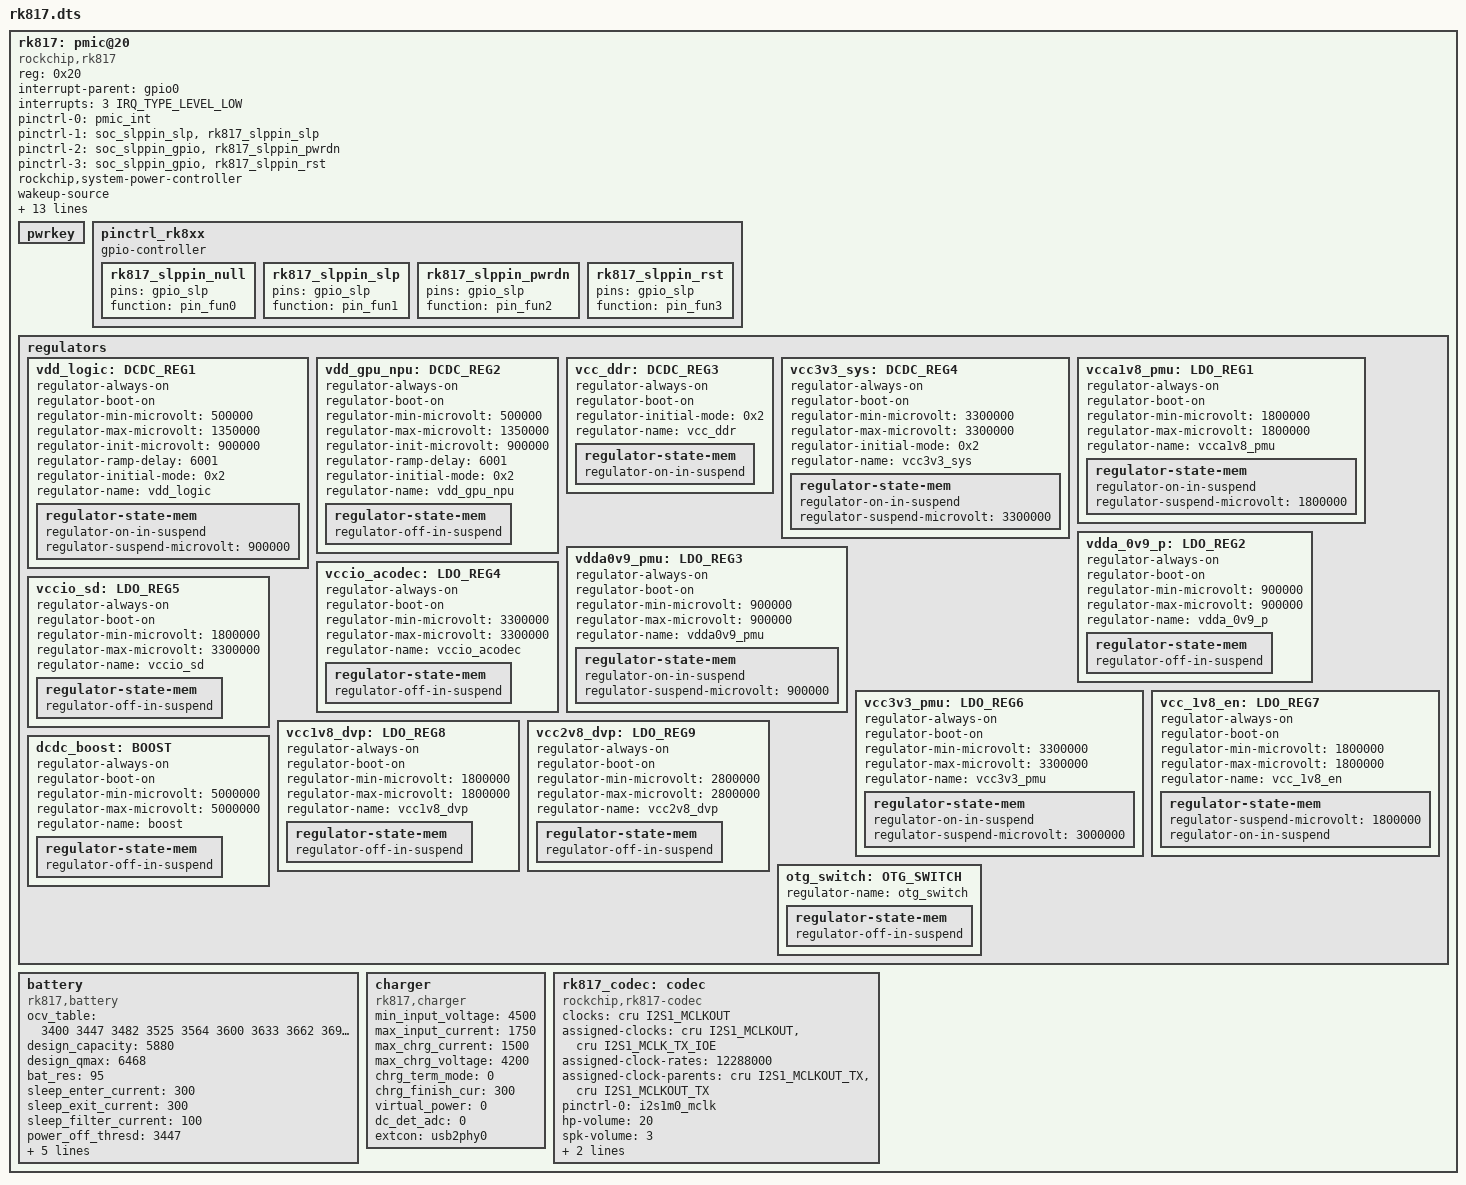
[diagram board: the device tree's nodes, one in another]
	rk817: pmic@20 {
		compatible = "rockchip,rk817";
		reg = <0x20>;
		interrupt-parent = <&gpio0>;
		interrupts = <3 IRQ_TYPE_LEVEL_LOW>;

		pinctrl-names = "default", "pmic-sleep",
				"pmic-power-off", "pmic-reset";
		pinctrl-0 = <&pmic_int>;
		pinctrl-1 = <&soc_slppin_slp>, <&rk817_slppin_slp>;
		pinctrl-2 = <&soc_slppin_gpio>, <&rk817_slppin_pwrdn>;
		pinctrl-3 = <&soc_slppin_gpio>, <&rk817_slppin_rst>;
		rockchip,system-power-controller;
		wakeup-source;
		#clock-cells = <1>;
		clock-output-names = "rk808-clkout1", "rk808-clkout2";
		//fb-inner-reg-idxs = <2>;
		/* 1: rst regs (default in codes), 0: rst the pmic */
		pmic-reset-func = <0>;
		/* not save the PMIC_POWER_EN register in uboot */
		not-save-power-en = <1>;

		vcc1-supply = <&vcc_sys>;
		vcc2-supply = <&vcc_sys>;
		vcc3-supply = <&vcc_sys>;
		vcc4-supply = <&vcc_sys>;
		vcc5-supply = <&vcc_sys>;
		vcc6-supply = <&vcc_sys>;
		vcc7-supply = <&vcc_sys>;
		vcc8-supply = <&vcc_sys>;
		vcc9-supply = <&dcdc_boost>;

		pwrkey {
			status = "okay";
		};

		pinctrl_rk8xx: pinctrl_rk8xx {
			gpio-controller;
			#gpio-cells = <2>;

			rk817_slppin_null: rk817_slppin_null {
				pins = "gpio_slp";
				function = "pin_fun0";
			};

			rk817_slppin_slp: rk817_slppin_slp {
				pins = "gpio_slp";
				function = "pin_fun1";
			};

			rk817_slppin_pwrdn: rk817_slppin_pwrdn {
				pins = "gpio_slp";
				function = "pin_fun2";
			};

			rk817_slppin_rst: rk817_slppin_rst {
				pins = "gpio_slp";
				function = "pin_fun3";
			};
		};

		regulators {
			vdd_logic: DCDC_REG1 {
				regulator-always-on;
				regulator-boot-on;
				regulator-min-microvolt = <500000>;
				regulator-max-microvolt = <1350000>;
				regulator-init-microvolt = <900000>;
				regulator-ramp-delay = <6001>;
				regulator-initial-mode = <0x2>;
				regulator-name = "vdd_logic";
				regulator-state-mem {
					regulator-on-in-suspend;
					regulator-suspend-microvolt = <900000>;
				};
			};

			vdd_gpu_npu: DCDC_REG2 {
				regulator-always-on;
				regulator-boot-on;
				regulator-min-microvolt = <500000>;
				regulator-max-microvolt = <1350000>;
				regulator-init-microvolt = <900000>;
				regulator-ramp-delay = <6001>;
				regulator-initial-mode = <0x2>;
				regulator-name = "vdd_gpu_npu";
				regulator-state-mem {
					regulator-off-in-suspend;
				};
			};

			vcc_ddr: DCDC_REG3 {
				regulator-always-on;
				regulator-boot-on;
				regulator-initial-mode = <0x2>;
				regulator-name = "vcc_ddr";
				regulator-state-mem {
					regulator-on-in-suspend;
				};
			};

			vcc3v3_sys: DCDC_REG4 {
				regulator-always-on;
				regulator-boot-on;
				regulator-min-microvolt = <3300000>;
				regulator-max-microvolt = <3300000>;
				regulator-initial-mode = <0x2>;
				regulator-name = "vcc3v3_sys";
				regulator-state-mem {
					regulator-on-in-suspend;
					regulator-suspend-microvolt = <3300000>;
				};
			};

			vcca1v8_pmu: LDO_REG1 {
				regulator-always-on;
				regulator-boot-on;
				regulator-min-microvolt = <1800000>;
				regulator-max-microvolt = <1800000>;
				regulator-name = "vcca1v8_pmu";
				regulator-state-mem {
					regulator-on-in-suspend;
					regulator-suspend-microvolt = <1800000>;
				};
			};

			vdda_0v9_p: LDO_REG2 {
				regulator-always-on;
				regulator-boot-on;
				regulator-min-microvolt = <900000>;
				regulator-max-microvolt = <900000>;
				regulator-name = "vdda_0v9_p";
				regulator-state-mem {
					regulator-off-in-suspend;
				};
			};

			vdda0v9_pmu: LDO_REG3 {
				regulator-always-on;
				regulator-boot-on;
				regulator-min-microvolt = <900000>;
				regulator-max-microvolt = <900000>;
				regulator-name = "vdda0v9_pmu";
				regulator-state-mem {
					regulator-on-in-suspend;
					regulator-suspend-microvolt = <900000>;
				};
			};

			vccio_acodec: LDO_REG4 {
				regulator-always-on;
				regulator-boot-on;
				regulator-min-microvolt = <3300000>;
				regulator-max-microvolt = <3300000>;
				regulator-name = "vccio_acodec";
				regulator-state-mem {
					regulator-off-in-suspend;
				};
			};

			vccio_sd: LDO_REG5 {
				regulator-always-on;
				regulator-boot-on;
				regulator-min-microvolt = <1800000>;
				regulator-max-microvolt = <3300000>;
				regulator-name = "vccio_sd";
				regulator-state-mem {
					regulator-off-in-suspend;
				};
			};

			vcc3v3_pmu: LDO_REG6 {
				regulator-always-on;
				regulator-boot-on;
				regulator-min-microvolt = <3300000>;
				regulator-max-microvolt = <3300000>;
				regulator-name = "vcc3v3_pmu";
				regulator-state-mem {
					regulator-on-in-suspend;
					regulator-suspend-microvolt = <3000000>;
				};
			};

			vcc_1v8_en: LDO_REG7 {
				regulator-always-on;
				regulator-boot-on;
				regulator-min-microvolt = <1800000>;
				regulator-max-microvolt = <1800000>;
				regulator-name = "vcc_1v8_en";
				regulator-state-mem {
					regulator-suspend-microvolt = <1800000>;
					regulator-on-in-suspend;
				};
			};

			vcc1v8_dvp: LDO_REG8 {
				regulator-always-on;
				regulator-boot-on;
				regulator-min-microvolt = <1800000>;
				regulator-max-microvolt = <1800000>;
				regulator-name = "vcc1v8_dvp";
				regulator-state-mem {
					regulator-off-in-suspend;
				};
			};

			vcc2v8_dvp: LDO_REG9 {
				regulator-always-on;
				regulator-boot-on;
				regulator-min-microvolt = <2800000>;
				regulator-max-microvolt = <2800000>;
				regulator-name = "vcc2v8_dvp";
				regulator-state-mem {
					regulator-off-in-suspend;
				};
			};

			dcdc_boost: BOOST {
				regulator-always-on;
				regulator-boot-on;
				regulator-min-microvolt = <5000000>;
				regulator-max-microvolt = <5000000>;
				regulator-name = "boost";
				regulator-state-mem {
					regulator-off-in-suspend;
				};
				
				
			};

			otg_switch: OTG_SWITCH {
				regulator-name = "otg_switch";
				regulator-state-mem {
					regulator-off-in-suspend;
				};
			};
		};

    	battery {
			compatible = "rk817,battery";
            ocv_table = <3400 3447 3482 3525 3564 3600 3633 3662
						 3695 3732 3770 3814 3861 3900 3936 3978
						 4020 4054 4073 4099 4182 4195>;
            design_capacity = <5880>;
            design_qmax = <6468>;
			bat_res = <95>;
			sleep_enter_current = <300>;
			sleep_exit_current = <300>;
			sleep_filter_current = <100>;
			power_off_thresd = <3447>;
			zero_algorithm_vol = <3850>;
			max_soc_offset = <60>;
			monitor_sec = <5>;
			sample_res = <10>;
			virtual_power = <0>;
			status = "okay";
		};

		charger {
			compatible = "rk817,charger";
			min_input_voltage = <4500>;
			max_input_current = <1750>;
			max_chrg_current = <1500>;
			max_chrg_voltage = <4200>;
			chrg_term_mode = <0>;
			chrg_finish_cur = <300>;
			virtual_power = <0>;
			dc_det_adc = <0>;
			extcon = <&usb2phy0>;
			status = "okay";
		};

		rk817_codec: codec {
			#sound-dai-cells = <0>;
			compatible = "rockchip,rk817-codec";
			clocks = <&cru I2S1_MCLKOUT>;
			clock-names = "mclk";
			assigned-clocks = <&cru I2S1_MCLKOUT>, <&cru I2S1_MCLK_TX_IOE>;
			assigned-clock-rates = <12288000>;
			assigned-clock-parents = <&cru I2S1_MCLKOUT_TX>, <&cru I2S1_MCLKOUT_TX>;
			pinctrl-names = "default";
			pinctrl-0 = <&i2s1m0_mclk>;
			hp-volume = <20>;
			spk-volume = <3>;
			out-l2spk-r2hp;
			//spk-ctl-gpios = <&gpio0 RK_PA6 GPIO_ACTIVE_HIGH>;
			spk-ctl-gpios = <&gpio4 RK_PC2 GPIO_ACTIVE_HIGH>;
			status = "okay";
		};
	};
